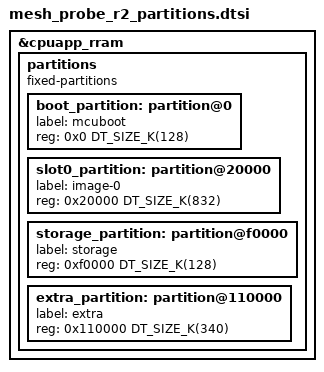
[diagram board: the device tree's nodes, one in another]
/*
 * Copyright (c) 2026 FoBE Studio
 *
 * SPDX-License-Identifier: Apache-2.0
 */

/* Shared application and MCUboot partition layout. */
&cpuapp_rram {
	/delete-node/ partitions;

	partitions {
		compatible = "fixed-partitions";
		#address-cells = <1>;
		#size-cells = <1>;
		ranges;

		boot_partition: partition@0 {
			label = "mcuboot";
			reg = <0x0 DT_SIZE_K(128)>;
		};

		slot0_partition: partition@20000 {
			label = "image-0";
			reg = <0x20000 DT_SIZE_K(832)>;
		};

		storage_partition: partition@f0000 {
			label = "storage";
			reg = <0xf0000 DT_SIZE_K(128)>;
		};

		extra_partition: partition@110000 {
			label = "extra";
			reg = <0x110000 DT_SIZE_K(340)>;
		};
	};
};
